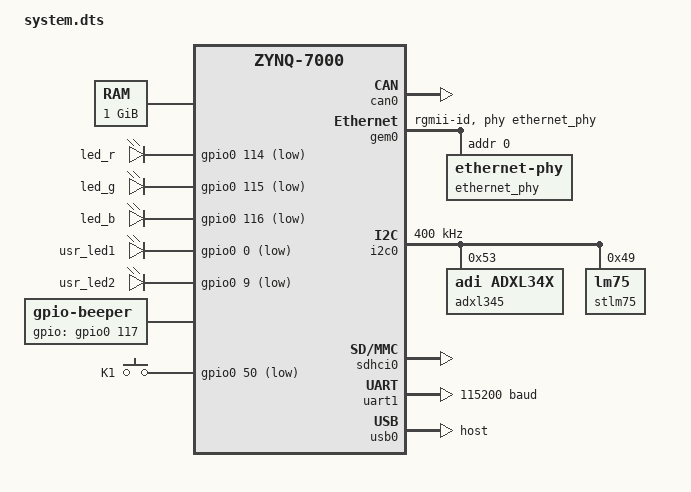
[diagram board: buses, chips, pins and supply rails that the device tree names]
/*
 * CAUTION: This file is automatically generated by Xilinx.
 * Version:  
 * Today is: Wed Apr 20 09:41:40 2016
*/


/dts-v1/;
/include/ "zynq-7000.dtsi"
/ {
	cpus {
		cpu@0 {
			operating-points = <666666 1000000 333333 1000000>;
		};
	};
	chosen {
		bootargs = "console=ttyPS0,115200 earlyprintk root=/dev/mmcblk0p2 rootwait";
	};
	aliases {
		ethernet0 = &gem0;
		serial0 = &uart1;
	};
	memory {
		device_type = "memory";
		reg = <0x0 0x40000000>;
	};
};
&can0 {
	status = "okay";
};
&gem0 {
	local-mac-address = [00 0a 35 00 00 00];
	phy-mode = "rgmii-id";
	status = "okay";
	xlnx,ptp-enet-clock = <0x69f6bcb>;
    phy-handle = <&ethernet_phy>;
    
    ethernet_phy: ethernet-phy@0 {
        reg = <0>;
    };
};
&gpio0 {
	emio-gpio-width = <64>;
	gpio-mask-high = <0x0>;
	gpio-mask-low = <0x5600>;
};
&i2c0 {
	clock-frequency = <400000>;
	status = "okay";
    adxl345@53 {
            compatible = "adi,adxl34x", "adxl34x";
            reg = <0x53>;
            interrupt-parent = <&intc>;
            interrupts = <0 29 4>;
    };

    stlm75@49 {
            status = "okay";
            compatible = "lm75";
            reg = <0x49>;
            interrupt-parent = <&intc>;
            interrupts = <0 30 4>;
    };
};
&intc {
	num_cpus = <2>;
	num_interrupts = <96>;
};
&sdhci0 {
	status = "okay";
	xlnx,has-cd = <0x1>;
	xlnx,has-power = <0x0>;
	xlnx,has-wp = <0x1>;
};
&uart1 {
	current-speed = <115200>;
	device_type = "serial";
	port-number = <0>;
	status = "okay";
};
&usb0 {
	dr_mode = "host";
	phy_type = "ulpi";
	status = "okay";
    xlnx,phy-reset-gpio = <&gpio0 50 0>; 
};
&clkc {
	fclk-enable = <0x1>;
	ps-clk-frequency = <33333333>;
};

/ {
    leds {
        compatible = "gpio-leds";

        led_r {
	        label = "led_r";
            /*
             * 54+(Gpio)60=114
             */
		    gpios = <&gpio0 114 1>;
		    default-state = "on";
		    linux,default-trigger = "heartbeat";
	    };

	    led_g {
		    label = "led_g";
            /*
             * 54+(Gpio)61=115
            */
		    gpios = <&gpio0 115 1>;
		    default-state = "on";
		    linux,default-trigger = "heartbeat";
	    };

	    led_b {
		    label = "led_b";
            /*
             * 54+(Gpio)62=116
             */
		    gpios = <&gpio0 116 1>;
		    default-state = "on";
		    linux,default-trigger = "heartbeat";
	    };

	    usr_led1 {
		    label = "usr_led1";
            /*
             * MIO0
             */
		    gpios = <&gpio0 0 1>;
    	    default-state = "off";
		    linux,default-trigger = "none";
	    };

	    usr_led2 {
		    label = "usr_led2";
            /*
             * MIO9
             */
		    gpios = <&gpio0 9 1>;
		    default-state = "off";
		    linux,default-trigger = "none";
	    };
    };

        gpio-beep {
	        compatible = "gpio-beeper";
	        lable = "pl-beep";
            /*
             * 54+(Gpio)63=117
             */
	        gpios = <&gpio0 117 0>;
        };

        gpio-keys {
	        compatible = "gpio-keys";
	        #address-cells = <0x1>;
	        #size-cells = <0x0>;
	        autorepeat;

	        K1 {
		        label = "K1";
				/*
				 * MIO50
                 */
		        gpios = <&gpio0 50 1>;
		        linux,code = <0x66>;
		        gpio-key,wakeup;
		        autorepeat;
	        };
        };
};
